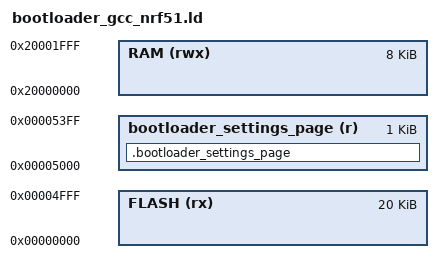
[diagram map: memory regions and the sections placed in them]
/* Linker script to configure memory regions. */

SEARCH_DIR(.)
GROUP(-lgcc -lc -lnosys)

MEMORY
{
  FLASH (rx) : ORIGIN = 0x0, LENGTH = 0x5000
  RAM (rwx) :  ORIGIN = 0x20000000, LENGTH = 0x2000
  bootloader_settings_page (r) : ORIGIN = 0x00005000, LENGTH = 0x0400
}

SECTIONS
{
  .bootloader_settings_page(NOLOAD) :
  {
    PROVIDE(__start_bootloader_settings_page = .);
    KEEP(*(SORT(.bootloader_settings_page*)))
    PROVIDE(__stop_bootloader_settings_page = .);
  } > bootloader_settings_page
}

SECTIONS
{
  . = ALIGN(4);
  .mem_section_dummy_ram :
  {
  }

} INSERT AFTER .data;

SECTIONS
{
  .mem_section_dummy_rom :
  {
  }
  

} INSERT AFTER .text

INCLUDE "nrf_common.ld"
